AUTOSAR XML (schema 00048)
package /HuaweiMDC/FunctionalSoftware/LidarSlam/Execution
  executable LidarSlamExecutable
    root sw component prototype LidarSlamSwComponent: application-type=LidarSlamApplicationSwComponent
package /HuaweiMDC/FunctionalSoftware/LidarSlam/SwComponent
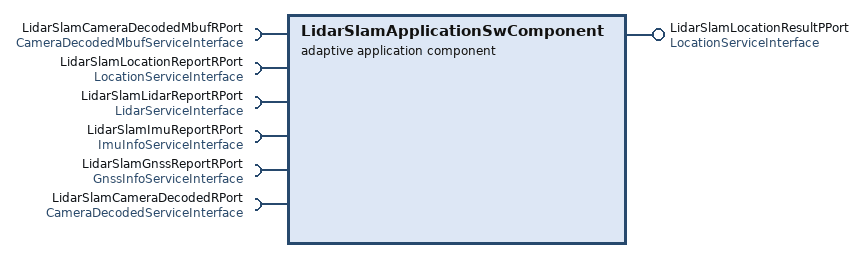
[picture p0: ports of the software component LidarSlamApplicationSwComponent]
  adaptive application sw component type LidarSlamApplicationSwComponent
    require port LidarSlamCameraDecodedMbufRPort: required-interface=CameraDecodedMbufServiceInterface
    require port LidarSlamLocationReportRPort: required-interface=LocationServiceInterface
    provide port LidarSlamLocationResultPPort: provided-interface=LocationServiceInterface
    4 x require port:
      LidarSlamLidarReportRPort: required-interface=LidarServiceInterface
      LidarSlamImuReportRPort: required-interface=ImuInfoServiceInterface
      LidarSlamGnssReportRPort: required-interface=GnssInfoServiceInterface
      LidarSlamCameraDecodedRPort: required-interface=CameraDecodedServiceInterface
